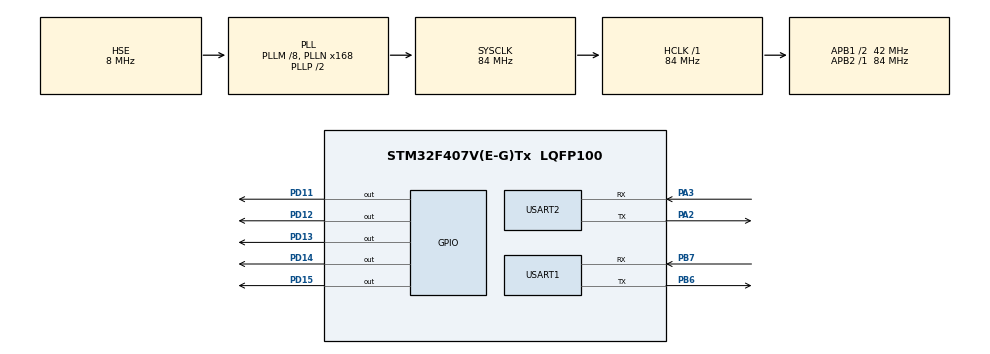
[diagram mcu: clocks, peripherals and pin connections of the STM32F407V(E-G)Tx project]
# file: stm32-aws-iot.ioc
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Dma.Request0=USART2_RX
Dma.Request1=USART1_RX
Dma.USART1_RX.1.Direction=DMA_PERIPH_TO_MEMORY
Dma.USART1_RX.1.FIFOMode=DMA_FIFOMODE_DISABLE
Dma.USART1_RX.1.Instance=DMA2_Stream2
Dma.USART1_RX.1.MemDataAlignment=DMA_MDATAALIGN_BYTE
Dma.USART1_RX.1.MemInc=DMA_MINC_ENABLE
Dma.USART1_RX.1.Mode=DMA_CIRCULAR
Dma.USART1_RX.1.PeriphDataAlignment=DMA_PDATAALIGN_BYTE
Dma.USART1_RX.1.PeriphInc=DMA_PINC_DISABLE
Dma.USART1_RX.1.Priority=DMA_PRIORITY_LOW
Dma.USART2_RX.0.Direction=DMA_PERIPH_TO_MEMORY
Dma.USART2_RX.0.FIFOMode=DMA_FIFOMODE_DISABLE
Dma.USART2_RX.0.Instance=DMA1_Stream5
Dma.USART2_RX.0.MemDataAlignment=DMA_MDATAALIGN_BYTE
Dma.USART2_RX.0.MemInc=DMA_MINC_ENABLE
Dma.USART2_RX.0.Mode=DMA_CIRCULAR
Dma.USART2_RX.0.PeriphDataAlignment=DMA_PDATAALIGN_BYTE
Dma.USART2_RX.0.PeriphInc=DMA_PINC_DISABLE
Dma.USART2_RX.0.Priority=DMA_PRIORITY_LOW
FREERTOS.Tasks01=APPLICATION,24,512,appTask,Default,NULL,Dynamic,NULL,NULL;SYSTEM,32,1024,systemTask,Default,NULL,Dynamic,NULL,NULL
FREERTOS.configTICK_RATE_HZ=100
FREERTOS.configUSE_PREEMPTION=1
Mcu.Family=STM32F4
Mcu.Name=STM32F407V(E-G)Tx
Mcu.Package=LQFP100
NVIC.DMA1_Stream5_IRQn=true\:5\:0\:false\:false\:true\:true\:false\:true
NVIC.DMA2_Stream2_IRQn=true\:5\:0\:false\:false\:true\:true\:false\:true
NVIC.PriorityGroup=NVIC_PRIORITYGROUP_4
NVIC.TIM7_IRQn=true\:15\:0\:false\:false\:true\:false\:false\:true
NVIC.TimeBase=TIM7_IRQn
NVIC.TimeBaseIP=TIM7
PA13.Mode=Serial_Wire
PA13.Signal=SYS_JTMS-SWDIO
PA14.Mode=Serial_Wire
PA14.Signal=SYS_JTCK-SWCLK
PA2.Mode=Asynchronous
PA2.Signal=USART2_TX
PA3.Mode=Asynchronous
PA3.Signal=USART2_RX
PB6.Mode=Asynchronous
PB6.Signal=USART1_TX
PB7.Mode=Asynchronous
PB7.Signal=USART1_RX
PD11.Signal=GPIO_Output
PD12.Signal=GPIO_Output
PD13.Signal=GPIO_Output
PD14.Signal=GPIO_Output
PD15.Signal=GPIO_Output
PH0-OSC_IN.Mode=HSE-External-Oscillator
PH0-OSC_IN.Signal=RCC_OSC_IN
PH1-OSC_OUT.Mode=HSE-External-Oscillator
PH1-OSC_OUT.Signal=RCC_OSC_OUT
ProjectManager.HeapSize=0x2000
ProjectManager.StackSize=0x4000
ProjectManager.TargetToolchain=STM32CubeIDE
RCC.48MHZClocksFreq_Value=42000000
RCC.AHBFreq_Value=84000000
RCC.APB1CLKDivider=RCC_HCLK_DIV2
RCC.APB1Freq_Value=42000000
RCC.APB1TimFreq_Value=84000000
RCC.APB2Freq_Value=84000000
RCC.APB2TimFreq_Value=84000000
RCC.CortexFreq_Value=84000000
RCC.HCLKFreq_Value=84000000
RCC.HSE_VALUE=8000000
RCC.HSI_VALUE=16000000
RCC.LSE_VALUE=32768
RCC.PLLM=8
RCC.PLLN=168
RCC.PLLSourceVirtual=RCC_PLLSOURCE_HSE
RCC.SYSCLKFreq_VALUE=84000000
RCC.SYSCLKSource=RCC_SYSCLKSOURCE_PLLCLK
RCC.VCOOutputFreq_Value=168000000
USART1.VirtualMode=VM_ASYNC
USART2.VirtualMode=VM_ASYNC
VP_FREERTOS_VS_CMSIS_V2.Mode=CMSIS_V2
VP_SYS_VS_tim7.Mode=TIM7
board=custom

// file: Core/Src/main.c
/* USER CODE BEGIN Header */
/**
  ******************************************************************************
  * @file           : main.c
  * @brief          : Main program body
  ******************************************************************************
  * @attention
  *
  * <h2><center>&copy; Copyright (c) 2021 STMicroelectronics.
  * All rights reserved.</center></h2>
  *
  * This software component is licensed by ST under BSD 3-Clause license,
  * the "License"; You may not use this file except in compliance with the
  * License. You may obtain a copy of the License at:
  *                        opensource.org/licenses/BSD-3-Clause
  *
  ******************************************************************************
  */
/* USER CODE END Header */
#include "main.h"
#include "cmsis_os.h"

/* USER CODE BEGIN Includes */
#include <stdio.h>
#include <string.h>

#include "app_config.h"

#include "lib_print.h"
#include "lib_system.h"
#include "lib_delay.h"
/* USER CODE END Includes */
#define thisModule APP_MODULE_MAIN

UART_HandleTypeDef huart1;
UART_HandleTypeDef huart2;
DMA_HandleTypeDef hdma_usart1_rx;
DMA_HandleTypeDef hdma_usart2_rx;

/* Definitions for APPLICATION */
osThreadId_t APPLICATIONHandle;
const osThreadAttr_t APPLICATION_attributes = {
    .name = "APPLICATION",
    .stack_size = 512 * 4,
    .priority = (osPriority_t)osPriorityNormal,
};
/* Definitions for SYSTEM */
osThreadId_t SYSTEMHandle;
const osThreadAttr_t SYSTEM_attributes = {
    .name = "SYSTEM",
    .stack_size = 1024 * 4,
    .priority = (osPriority_t)osPriorityAboveNormal,
};

void SystemClock_Config(void);
static void MX_GPIO_Init(void);
static void MX_DMA_Init(void);
static void MX_USART2_UART_Init(void);
static void MX_USART1_UART_Init(void);
void appTask(void *argument);
void systemTask(void *argument);

/* USER CODE BEGIN PFP */
void HAL_UART_RxCpltCallback(UART_HandleTypeDef *huart);

/* USER CODE END PFP */

int main(void)
{

    /* MCU Configuration--------------------------------------------------------*/

    /* Reset of all peripherals, Initializes the Flash interface and the Systick. */
    HAL_Init();

    /* Configure the system clock */
    SystemClock_Config();

    /* Initialize all configured peripherals */
    MX_GPIO_Init();
    MX_DMA_Init();
    MX_USART2_UART_Init();
    MX_USART1_UART_Init();

    /* Init scheduler */
    osKernelInitialize();

    /* Create the thread(s) */
    /* creation of APPLICATION */
    APPLICATIONHandle = osThreadNew(appTask, NULL, &APPLICATION_attributes);

    /* creation of SYSTEM */
    SYSTEMHandle = osThreadNew(systemTask, NULL, &SYSTEM_attributes);

    /* Start scheduler */
    osKernelStart();

    /* We should never get here as control is now taken by the scheduler */
    /* Infinite loop */
    while (1)
    {
    }

}

void SystemClock_Config(void)
{
    RCC_OscInitTypeDef RCC_OscInitStruct = {0};
    RCC_ClkInitTypeDef RCC_ClkInitStruct = {0};

    /** Configure the main internal regulator output voltage
  */
    __HAL_RCC_PWR_CLK_ENABLE();
    __HAL_PWR_VOLTAGESCALING_CONFIG(PWR_REGULATOR_VOLTAGE_SCALE1);
    /** Initializes the RCC Oscillators according to the specified parameters
  * in the RCC_OscInitTypeDef structure.
  */
    RCC_OscInitStruct.OscillatorType = RCC_OSCILLATORTYPE_HSE;
    RCC_OscInitStruct.HSEState = RCC_HSE_ON;
    RCC_OscInitStruct.PLL.PLLState = RCC_PLL_ON;
    RCC_OscInitStruct.PLL.PLLSource = RCC_PLLSOURCE_HSE;
    RCC_OscInitStruct.PLL.PLLM = 8;
    RCC_OscInitStruct.PLL.PLLN = 168;
    RCC_OscInitStruct.PLL.PLLP = RCC_PLLP_DIV2;
    RCC_OscInitStruct.PLL.PLLQ = 4;
    if (HAL_RCC_OscConfig(&RCC_OscInitStruct) != HAL_OK)
    {
        Error_Handler();
    }
    /** Initializes the CPU, AHB and APB buses clocks
  */
    RCC_ClkInitStruct.ClockType = RCC_CLOCKTYPE_HCLK | RCC_CLOCKTYPE_SYSCLK | RCC_CLOCKTYPE_PCLK1 | RCC_CLOCKTYPE_PCLK2;
    RCC_ClkInitStruct.SYSCLKSource = RCC_SYSCLKSOURCE_PLLCLK;
    RCC_ClkInitStruct.AHBCLKDivider = RCC_SYSCLK_DIV1;
    RCC_ClkInitStruct.APB1CLKDivider = RCC_HCLK_DIV2;
    RCC_ClkInitStruct.APB2CLKDivider = RCC_HCLK_DIV1;

    if (HAL_RCC_ClockConfig(&RCC_ClkInitStruct, FLASH_LATENCY_2) != HAL_OK)
    {
        Error_Handler();
    }
}

static void MX_USART1_UART_Init(void)
{

    huart1.Instance = USART1;
    huart1.Init.BaudRate = 115200;
    huart1.Init.WordLength = UART_WORDLENGTH_8B;
    huart1.Init.StopBits = UART_STOPBITS_1;
    huart1.Init.Parity = UART_PARITY_NONE;
    huart1.Init.Mode = UART_MODE_TX_RX;
    huart1.Init.HwFlowCtl = UART_HWCONTROL_NONE;
    huart1.Init.OverSampling = UART_OVERSAMPLING_16;
    if (HAL_UART_Init(&huart1) != HAL_OK)
    {
        Error_Handler();
    }
}

static void MX_USART2_UART_Init(void)
{

    huart2.Instance = USART2;
    huart2.Init.BaudRate = 115200;
    huart2.Init.WordLength = UART_WORDLENGTH_8B;
    huart2.Init.StopBits = UART_STOPBITS_1;
    huart2.Init.Parity = UART_PARITY_NONE;
    huart2.Init.Mode = UART_MODE_TX_RX;
    huart2.Init.HwFlowCtl = UART_HWCONTROL_NONE;
    huart2.Init.OverSampling = UART_OVERSAMPLING_16;
    if (HAL_UART_Init(&huart2) != HAL_OK)
    {
        Error_Handler();
    }
}

static void MX_DMA_Init(void)
{

    /* DMA controller clock enable */
    __HAL_RCC_DMA1_CLK_ENABLE();
    __HAL_RCC_DMA2_CLK_ENABLE();

    /* DMA interrupt init */
    /* DMA1_Stream5_IRQn interrupt configuration */
    HAL_NVIC_SetPriority(DMA1_Stream5_IRQn, 5, 0);
    HAL_NVIC_EnableIRQ(DMA1_Stream5_IRQn);
    /* DMA2_Stream2_IRQn interrupt configuration */
    HAL_NVIC_SetPriority(DMA2_Stream2_IRQn, 5, 0);
    HAL_NVIC_EnableIRQ(DMA2_Stream2_IRQn);
}

static void MX_GPIO_Init(void)
{
    GPIO_InitTypeDef GPIO_InitStruct = {0};

    /* GPIO Ports Clock Enable */
    __HAL_RCC_GPIOH_CLK_ENABLE();
    __HAL_RCC_GPIOA_CLK_ENABLE();
    __HAL_RCC_GPIOD_CLK_ENABLE();
    __HAL_RCC_GPIOB_CLK_ENABLE();

    /*Configure GPIO pin Output Level */
    HAL_GPIO_WritePin(GPIOD, GPIO_PIN_11 | GPIO_PIN_12 | GPIO_PIN_13 | GPIO_PIN_14 | GPIO_PIN_15, GPIO_PIN_RESET);

    /*Configure GPIO pins : PD11 PD12 PD13 PD14
                           PD15 */
    GPIO_InitStruct.Pin = GPIO_PIN_11 | GPIO_PIN_12 | GPIO_PIN_13 | GPIO_PIN_14 | GPIO_PIN_15;
    GPIO_InitStruct.Mode = GPIO_MODE_OUTPUT_PP;
    GPIO_InitStruct.Pull = GPIO_NOPULL;
    GPIO_InitStruct.Speed = GPIO_SPEED_FREQ_LOW;
    HAL_GPIO_Init(GPIOD, &GPIO_InitStruct);
}

void appTask(void *argument)
{
    /* USER CODE BEGIN 5 */

    app_main();
    /* Infinite loop */
    for (;;)
    {
        TASK_DELAY_MS(200);
    }
    /* USER CODE END 5 */
}

void systemTask(void *argument)
{

    sys_init();
    /* Infinite loop */
    for (;;)
    {
        TASK_DELAY_MS(10);
        SYSTEM_sync();
    }
    /* USER CODE END systemTask */
}

void HAL_TIM_PeriodElapsedCallback(TIM_HandleTypeDef *htim)
{
    if (htim->Instance == TIM7)
    {
        HAL_IncTick();
    }
}

void Error_Handler(void)
{
    __disable_irq();
    while (1)
    {
    }
}

/************************ (C) COPYRIGHT STMicroelectronics *****END OF FILE****/
